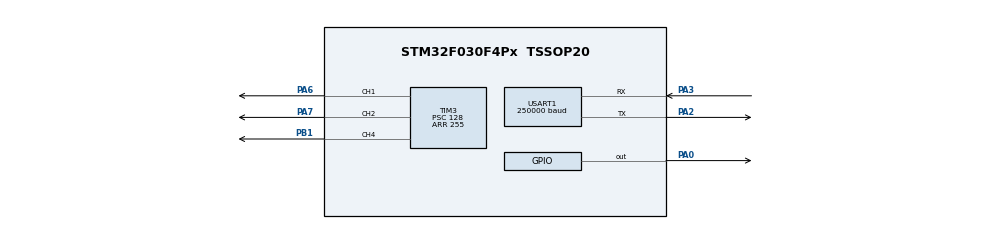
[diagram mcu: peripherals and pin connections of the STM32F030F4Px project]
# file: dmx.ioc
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Mcu.Family=STM32F0
Mcu.Name=STM32F030F4Px
Mcu.Package=TSSOP20
NVIC.USART1_IRQn=true\:0\:0\:false\:false\:true
PA0.Signal=GPIO_Output
PA2.Mode=Asynchronous
PA2.Signal=USART1_TX
PA3.Mode=Asynchronous
PA3.Signal=USART1_RX
PA6.GPIO_ModeDefaultPP=GPIO_MODE_AF_PP
PA6.Signal=S_TIM3_CH1
PA7.GPIO_ModeDefaultPP=GPIO_MODE_AF_PP
PA7.Signal=S_TIM3_CH2
PB1.GPIO_ModeDefaultPP=GPIO_MODE_AF_PP
PB1.Signal=S_TIM3_CH4
ProjectManager.HeapSize=0x200
ProjectManager.StackSize=0x400
ProjectManager.TargetToolchain=SW4STM32
RCC.AHBCLKDivider=RCC_SYSCLK_DIV4
RCC.AHBFreq_Value=2000000
RCC.APB1Freq_Value=2000000
RCC.APB1TimFreq_Value=2000000
RCC.HCLKFreq_Value=2000000
SH.S_TIM3_CH1.0=TIM3_CH1,PWM Generation1 CH1
SH.S_TIM3_CH2.0=TIM3_CH2,PWM Generation2 CH2
SH.S_TIM3_CH4.0=TIM3_CH4,PWM Generation4 CH4
TIM3.Channel-PWM\ Generation1\ CH1=TIM_CHANNEL_1
TIM3.Channel-PWM\ Generation2\ CH2=TIM_CHANNEL_2
TIM3.Channel-PWM\ Generation4\ CH4=TIM_CHANNEL_4
TIM3.OCPolarity_1=TIM_OCPOLARITY_LOW
TIM3.OCPolarity_2=TIM_OCPOLARITY_LOW
TIM3.OCPolarity_4=TIM_OCPOLARITY_LOW
TIM3.Period=255
TIM3.Prescaler=128
TIM3.Pulse-PWM\ Generation1\ CH1=127
TIM3.Pulse-PWM\ Generation2\ CH2=127
TIM3.Pulse-PWM\ Generation4\ CH4=127
USART1.BaudRate=250000
USART1.OverSampling=UART_OVERSAMPLING_8
USART1.VirtualMode-Asynchronous=VM_ASYNC
board=dmx

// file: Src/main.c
/**
  ******************************************************************************
  * File Name          : main.c
  * Description        : Main program body
  ******************************************************************************
  ** This notice applies to any and all portions of this file
  * that are not between comment pairs USER CODE BEGIN and
  * USER CODE END. Other portions of this file, whether
  * inserted by the user or by software development tools
  * are owned by their respective copyright owners.
  *
  * COPYRIGHT(c) 2017 STMicroelectronics
  *
  * Redistribution and use in source and binary forms, with or without modification,
  * are permitted provided that the following conditions are met:
  *   1. Redistributions of source code must retain the above copyright notice,
  *      this list of conditions and the following disclaimer.
  *   2. Redistributions in binary form must reproduce the above copyright notice,
  *      this list of conditions and the following disclaimer in the documentation
  *      and/or other materials provided with the distribution.
  *   3. Neither the name of STMicroelectronics nor the names of its contributors
  *      may be used to endorse or promote products derived from this software
  *      without specific prior written permission.
  *
  * THIS SOFTWARE IS PROVIDED BY THE COPYRIGHT HOLDERS AND CONTRIBUTORS "AS IS"
  * AND ANY EXPRESS OR IMPLIED WARRANTIES, INCLUDING, BUT NOT LIMITED TO, THE
  * IMPLIED WARRANTIES OF MERCHANTABILITY AND FITNESS FOR A PARTICULAR PURPOSE ARE
  * DISCLAIMED. IN NO EVENT SHALL THE COPYRIGHT HOLDER OR CONTRIBUTORS BE LIABLE
  * FOR ANY DIRECT, INDIRECT, INCIDENTAL, SPECIAL, EXEMPLARY, OR CONSEQUENTIAL
  * DAMAGES (INCLUDING, BUT NOT LIMITED TO, PROCUREMENT OF SUBSTITUTE GOODS OR
  * SERVICES; LOSS OF USE, DATA, OR PROFITS; OR BUSINESS INTERRUPTION) HOWEVER
  * CAUSED AND ON ANY THEORY OF LIABILITY, WHETHER IN CONTRACT, STRICT LIABILITY,
  * OR TORT (INCLUDING NEGLIGENCE OR OTHERWISE) ARISING IN ANY WAY OUT OF THE USE
  * OF THIS SOFTWARE, EVEN IF ADVISED OF THE POSSIBILITY OF SUCH DAMAGE.
  *
  ******************************************************************************
  */
#include "main.h"
#include "stm32f0xx_hal.h"

TIM_HandleTypeDef htim3;

UART_HandleTypeDef huart1;

/* USER CODE BEGIN PV */
/* Private variables ---------------------------------------------------------*/

/* USER CODE END PV */

void SystemClock_Config(void);
static void MX_GPIO_Init(void);
static void MX_USART1_UART_Init(void);
static void MX_TIM3_Init(void);
void HAL_TIM_MspPostInit(TIM_HandleTypeDef *htim);

/* USER CODE BEGIN PFP */
/* Private function prototypes -----------------------------------------------*/

/* USER CODE END PFP */

int main(void)
{

  /* MCU Configuration----------------------------------------------------------*/

  /* Reset of all peripherals, Initializes the Flash interface and the Systick. */
  HAL_Init();

  /* Configure the system clock */
  SystemClock_Config();

  /* Initialize all configured peripherals */
  MX_GPIO_Init();
  MX_USART1_UART_Init();
  MX_TIM3_Init();

  /* USER CODE BEGIN 2 */
  HAL_TIM_PWM_Start(&htim3, TIM_CHANNEL_1);
  HAL_TIM_PWM_Start(&htim3, TIM_CHANNEL_2);
  HAL_TIM_PWM_Start(&htim3, TIM_CHANNEL_4);

  /* Enable the UART Error Interrupt: (Frame error, noise error, overrun error) */
  SET_BIT(USART1->CR3, USART_CR3_EIE);

  /* Enable the UART Parity Error and Data Register not empty Interrupts */
  SET_BIT(USART1->CR1, USART_CR1_PEIE | USART_CR1_RXNEIE);
  /* USER CODE END 2 */

  /* Infinite loop */
  /* USER CODE BEGIN WHILE */
  while (1)
  {
	  HAL_PWR_EnterSLEEPMode(0, PWR_SLEEPENTRY_WFI);
  /* USER CODE END WHILE */

  }

}

/** System Clock Configuration
*/
void SystemClock_Config(void)
{

  RCC_OscInitTypeDef RCC_OscInitStruct;
  RCC_ClkInitTypeDef RCC_ClkInitStruct;
  RCC_PeriphCLKInitTypeDef PeriphClkInit;

    /**Initializes the CPU, AHB and APB busses clocks
    */
  RCC_OscInitStruct.OscillatorType = RCC_OSCILLATORTYPE_HSI;
  RCC_OscInitStruct.HSIState = RCC_HSI_ON;
  RCC_OscInitStruct.HSICalibrationValue = 16;
  RCC_OscInitStruct.PLL.PLLState = RCC_PLL_NONE;
  if (HAL_RCC_OscConfig(&RCC_OscInitStruct) != HAL_OK)
  {
    _Error_Handler(__FILE__, __LINE__);
  }

    /**Initializes the CPU, AHB and APB busses clocks
    */
  RCC_ClkInitStruct.ClockType = RCC_CLOCKTYPE_HCLK|RCC_CLOCKTYPE_SYSCLK
                              |RCC_CLOCKTYPE_PCLK1;
  RCC_ClkInitStruct.SYSCLKSource = RCC_SYSCLKSOURCE_HSI;
  RCC_ClkInitStruct.AHBCLKDivider = RCC_SYSCLK_DIV4;
  RCC_ClkInitStruct.APB1CLKDivider = RCC_HCLK_DIV1;

  if (HAL_RCC_ClockConfig(&RCC_ClkInitStruct, FLASH_LATENCY_0) != HAL_OK)
  {
    _Error_Handler(__FILE__, __LINE__);
  }

  PeriphClkInit.PeriphClockSelection = RCC_PERIPHCLK_USART1;
  PeriphClkInit.Usart1ClockSelection = RCC_USART1CLKSOURCE_PCLK1;
  if (HAL_RCCEx_PeriphCLKConfig(&PeriphClkInit) != HAL_OK)
  {
    _Error_Handler(__FILE__, __LINE__);
  }

    /**Configure the Systick interrupt time
    */
  HAL_SYSTICK_Config(HAL_RCC_GetHCLKFreq()/1000);

    /**Configure the Systick
    */
  HAL_SYSTICK_CLKSourceConfig(SYSTICK_CLKSOURCE_HCLK);

  /* SysTick_IRQn interrupt configuration */
  HAL_NVIC_SetPriority(SysTick_IRQn, 0, 0);
}

/* TIM3 init function */
static void MX_TIM3_Init(void)
{

  TIM_MasterConfigTypeDef sMasterConfig;
  TIM_OC_InitTypeDef sConfigOC;

  htim3.Instance = TIM3;
  htim3.Init.Prescaler = 128;
  htim3.Init.CounterMode = TIM_COUNTERMODE_UP;
  htim3.Init.Period = 255;
  htim3.Init.ClockDivision = TIM_CLOCKDIVISION_DIV1;
  htim3.Init.AutoReloadPreload = TIM_AUTORELOAD_PRELOAD_DISABLE;
  if (HAL_TIM_PWM_Init(&htim3) != HAL_OK)
  {
    _Error_Handler(__FILE__, __LINE__);
  }

  sMasterConfig.MasterOutputTrigger = TIM_TRGO_RESET;
  sMasterConfig.MasterSlaveMode = TIM_MASTERSLAVEMODE_DISABLE;
  if (HAL_TIMEx_MasterConfigSynchronization(&htim3, &sMasterConfig) != HAL_OK)
  {
    _Error_Handler(__FILE__, __LINE__);
  }

  sConfigOC.OCMode = TIM_OCMODE_PWM1;
  sConfigOC.Pulse = 127;
  sConfigOC.OCPolarity = TIM_OCPOLARITY_LOW;
  sConfigOC.OCFastMode = TIM_OCFAST_DISABLE;
  if (HAL_TIM_PWM_ConfigChannel(&htim3, &sConfigOC, TIM_CHANNEL_1) != HAL_OK)
  {
    _Error_Handler(__FILE__, __LINE__);
  }

  if (HAL_TIM_PWM_ConfigChannel(&htim3, &sConfigOC, TIM_CHANNEL_2) != HAL_OK)
  {
    _Error_Handler(__FILE__, __LINE__);
  }

  if (HAL_TIM_PWM_ConfigChannel(&htim3, &sConfigOC, TIM_CHANNEL_4) != HAL_OK)
  {
    _Error_Handler(__FILE__, __LINE__);
  }

  HAL_TIM_MspPostInit(&htim3);

}

/* USART1 init function */
static void MX_USART1_UART_Init(void)
{

  huart1.Instance = USART1;
  huart1.Init.BaudRate = 250000;
  huart1.Init.WordLength = UART_WORDLENGTH_8B;
  huart1.Init.StopBits = UART_STOPBITS_1;
  huart1.Init.Parity = UART_PARITY_NONE;
  huart1.Init.Mode = UART_MODE_TX_RX;
  huart1.Init.HwFlowCtl = UART_HWCONTROL_NONE;
  huart1.Init.OverSampling = UART_OVERSAMPLING_8;
  huart1.Init.OneBitSampling = UART_ONE_BIT_SAMPLE_DISABLE;
  huart1.AdvancedInit.AdvFeatureInit = UART_ADVFEATURE_NO_INIT;
  if (HAL_UART_Init(&huart1) != HAL_OK)
  {
    _Error_Handler(__FILE__, __LINE__);
  }

}

/** Configure pins as
        * Analog
        * Input
        * Output
        * EVENT_OUT
        * EXTI
        * Free pins are configured automatically as Analog (this feature is enabled through
        * the Code Generation settings)
*/
static void MX_GPIO_Init(void)
{

  GPIO_InitTypeDef GPIO_InitStruct;

  /* GPIO Ports Clock Enable */
  __HAL_RCC_GPIOF_CLK_ENABLE();
  __HAL_RCC_GPIOA_CLK_ENABLE();
  __HAL_RCC_GPIOB_CLK_ENABLE();

  /*Configure GPIO pin Output Level */
  HAL_GPIO_WritePin(GPIOA, GPIO_PIN_0, GPIO_PIN_RESET);

  /*Configure GPIO pins : PF0 PF1 */
  GPIO_InitStruct.Pin = GPIO_PIN_0|GPIO_PIN_1;
  GPIO_InitStruct.Mode = GPIO_MODE_ANALOG;
  GPIO_InitStruct.Pull = GPIO_NOPULL;
  HAL_GPIO_Init(GPIOF, &GPIO_InitStruct);

  /*Configure GPIO pin : PA0 */
  GPIO_InitStruct.Pin = GPIO_PIN_0;
  GPIO_InitStruct.Mode = GPIO_MODE_OUTPUT_PP;
  GPIO_InitStruct.Pull = GPIO_NOPULL;
  GPIO_InitStruct.Speed = GPIO_SPEED_FREQ_LOW;
  HAL_GPIO_Init(GPIOA, &GPIO_InitStruct);

  /*Configure GPIO pins : PA1 PA4 PA5 PA9
                           PA10 PA13 PA14 */
  GPIO_InitStruct.Pin = GPIO_PIN_1|GPIO_PIN_4|GPIO_PIN_5|GPIO_PIN_9
                          |GPIO_PIN_10|GPIO_PIN_13|GPIO_PIN_14;
  GPIO_InitStruct.Mode = GPIO_MODE_ANALOG;
  GPIO_InitStruct.Pull = GPIO_NOPULL;
  HAL_GPIO_Init(GPIOA, &GPIO_InitStruct);

}

void _Error_Handler(char * file, int line)
{
  while(1)
  {
  }
}

/************************ (C) COPYRIGHT STMicroelectronics *****END OF FILE****/
